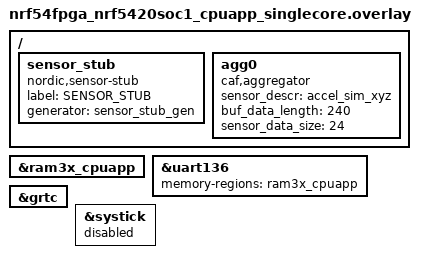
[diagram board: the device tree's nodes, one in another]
/*
 * Copyright (c) 2022 Nordic Semiconductor ASA
 *
 * SPDX-License-Identifier: LicenseRef-Nordic-5-Clause
 */

 /{
	sensor_stub: sensor_stub {
		compatible = "nordic,sensor-stub";
		label = "SENSOR_STUB";
		generator = "sensor_stub_gen";
		status = "okay";
	};

	agg0: agg0 {
		compatible = "caf,aggregator";
		sensor_descr = "accel_sim_xyz";
		buf_data_length = <240>;
		sensor_data_size = <24>;
		status = "okay";
	};
};

/* ram3x_cpuapp buffer is used by App core UART driver. */
&ram3x_cpuapp {
	status = "okay";
};

&uart136 {
	status = "okay";
	memory-regions = <&ram3x_cpuapp>;
};

&grtc {
	status = "okay";
};

/* Disable systick for App core, GRTC is used as tick source. */
&systick {
	status = "disabled";
};
